VERSION ""

NS_ :

BS_:

BU_:

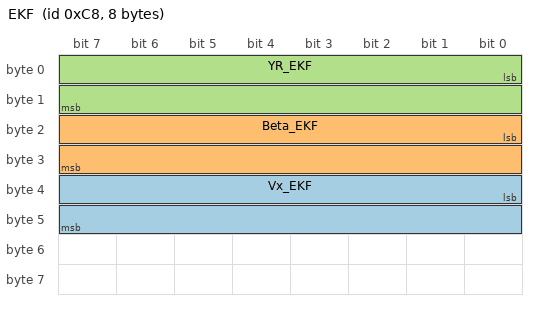
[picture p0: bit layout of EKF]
BO_ 200 EKF: 8 Vector__XXX
 SG_ Vx_EKF : 32|16@1- (0.01,0) [-327.68|327.67] "" Vector__XXX
 SG_ Beta_EKF : 16|16@1- (0.01,0) [-327.68|327.67] "deg" Vector__XXX
 SG_ YR_EKF : 0|16@1- (0.01,0) [-327.68|327.67] "deg/sec" Vector__XXX

BA_DEF_  "BusType" STRING ;
BA_DEF_DEF_  "BusType" "CAN";
